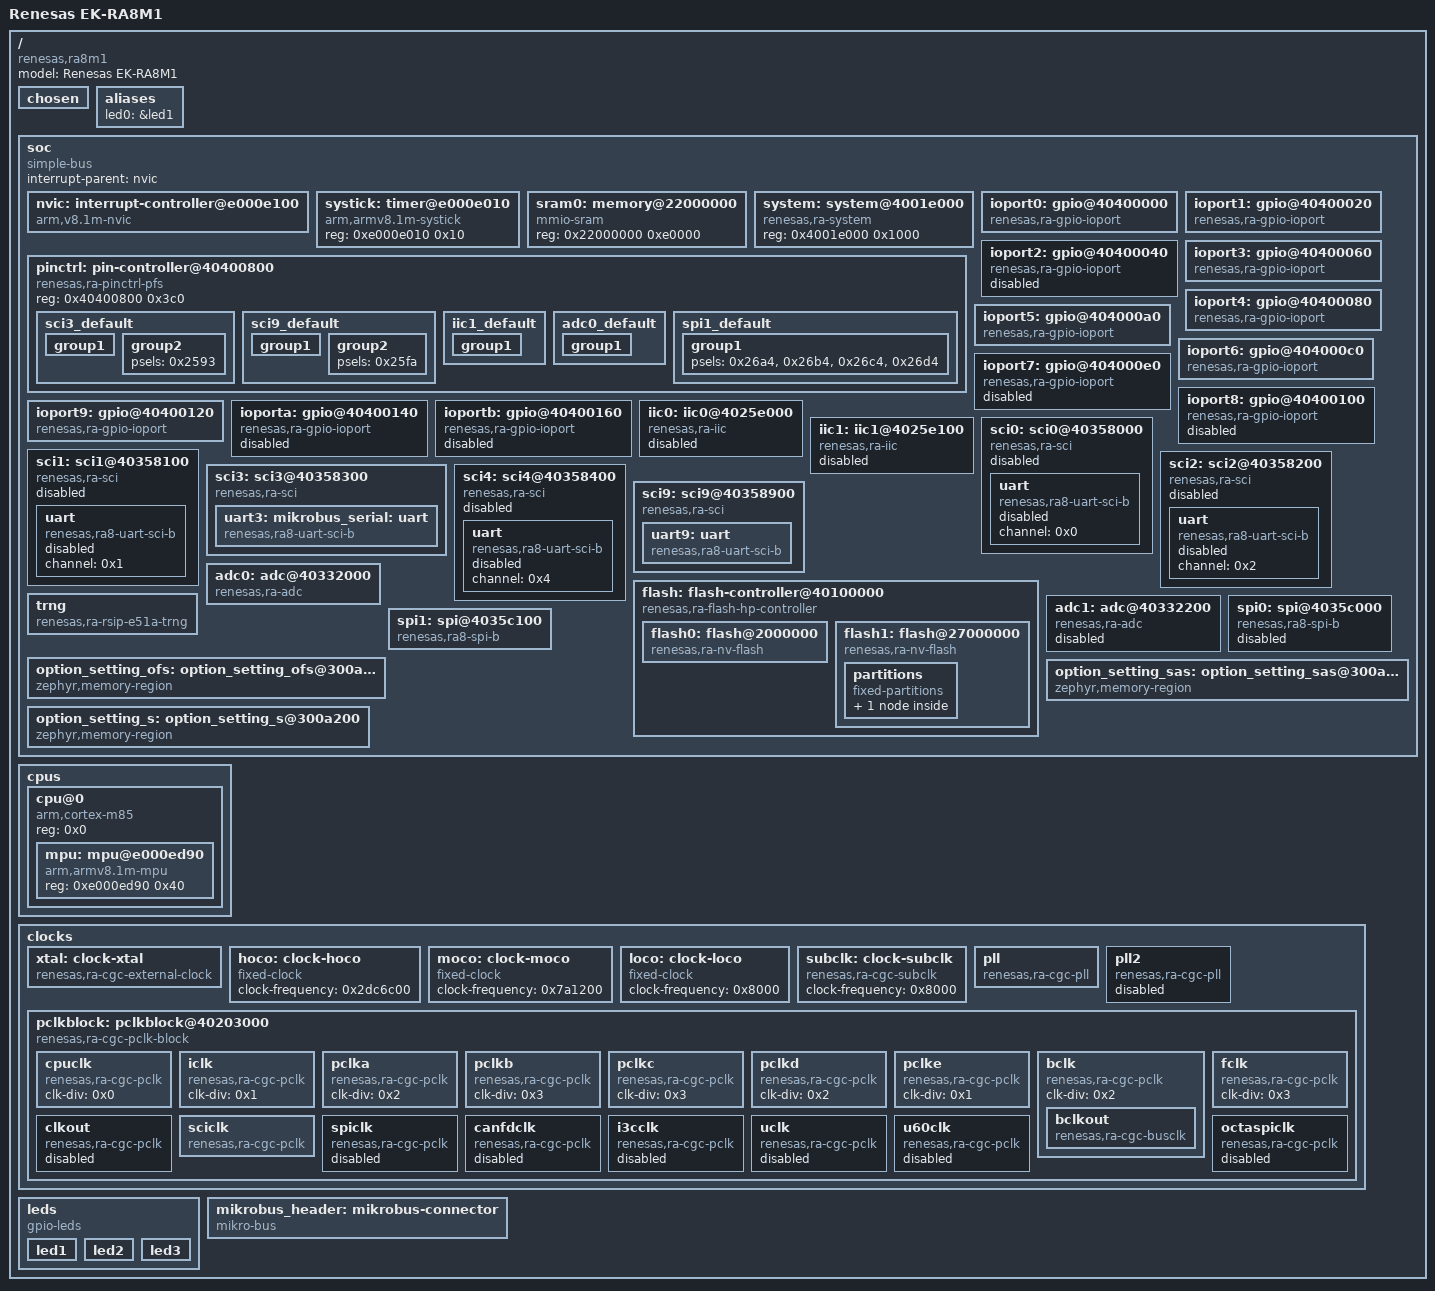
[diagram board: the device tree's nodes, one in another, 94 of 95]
/dts-v1/;

/ {
	#address-cells = < 0x1 >;
	#size-cells = < 0x1 >;
	model = "Renesas EK-RA8M1";
	compatible = "renesas,ra8m1", "renesas,ra8";
	chosen {
		zephyr,sram = &sram0;
		zephyr,flash-controller = &flash1;
		zephyr,flash = &flash0;
		zephyr,console = &uart9;
		zephyr,shell-uart = &uart9;
		zephyr,entropy = &trng;
	};
	aliases {
		led0 = &led1;
	};
	soc {
		#address-cells = < 0x1 >;
		#size-cells = < 0x1 >;
		compatible = "simple-bus";
		interrupt-parent = < &nvic >;
		ranges;
		nvic: interrupt-controller@e000e100 {
			#address-cells = < 0x1 >;
			compatible = "arm,v8.1m-nvic";
			reg = < 0xe000e100 0xc00 >;
			interrupt-controller;
			#interrupt-cells = < 0x2 >;
			arm,num-irq-priority-bits = < 0x4 >;
			phandle = < 0x1 >;
		};
		systick: timer@e000e010 {
			compatible = "arm,armv8.1m-systick";
			reg = < 0xe000e010 0x10 >;
		};
		sram0: memory@22000000 {
			compatible = "mmio-sram";
			reg = < 0x22000000 0xe0000 >;
		};
		system: system@4001e000 {
			compatible = "renesas,ra-system";
			reg = < 0x4001e000 0x1000 >;
			status = "okay";
		};
		pinctrl: pin-controller@40400800 {
			compatible = "renesas,ra-pinctrl-pfs";
			reg = < 0x40400800 0x3c0 >;
			status = "okay";
			sci3_default: sci3_default {
				phandle = < 0x4 >;
				group1 {
					psels = < 0x25a3 >;
					drive-strength = "medium";
				};
				group2 {
					psels = < 0x2593 >;
				};
			};
			sci9_default: sci9_default {
				phandle = < 0x5 >;
				group1 {
					psels = < 0x25ea >;
					drive-strength = "medium";
				};
				group2 {
					psels = < 0x25fa >;
				};
			};
			iic1_default: iic1_default {
				phandle = < 0x2 >;
				group1 {
					psels = < 0x27c5 >, < 0x27b5 >;
					drive-strength = "medium";
				};
			};
			adc0_default: adc0_default {
				phandle = < 0x6 >;
				group1 {
					psels = < 0x2040 >;
					renesas,analog-enable;
				};
			};
			spi1_default: spi1_default {
				phandle = < 0x8 >;
				group1 {
					psels = < 0x26a4 >, < 0x26b4 >, < 0x26c4 >, < 0x26d4 >;
				};
			};
		};
		ioport0: gpio@40400000 {
			compatible = "renesas,ra-gpio-ioport";
			reg = < 0x40400000 0x20 >;
			port = < 0x0 >;
			gpio-controller;
			#gpio-cells = < 0x2 >;
			ngpios = < 0x10 >;
			status = "okay";
			phandle = < 0xc >;
		};
		ioport1: gpio@40400020 {
			compatible = "renesas,ra-gpio-ioport";
			reg = < 0x40400020 0x20 >;
			port = < 0x1 >;
			gpio-controller;
			#gpio-cells = < 0x2 >;
			ngpios = < 0x10 >;
			status = "okay";
			phandle = < 0xb >;
		};
		ioport2: gpio@40400040 {
			compatible = "renesas,ra-gpio-ioport";
			reg = < 0x40400040 0x20 >;
			port = < 0x2 >;
			gpio-controller;
			#gpio-cells = < 0x2 >;
			ngpios = < 0x10 >;
			status = "disabled";
		};
		ioport3: gpio@40400060 {
			compatible = "renesas,ra-gpio-ioport";
			reg = < 0x40400060 0x20 >;
			port = < 0x3 >;
			gpio-controller;
			#gpio-cells = < 0x2 >;
			ngpios = < 0x10 >;
			status = "okay";
			phandle = < 0xf >;
		};
		ioport4: gpio@40400080 {
			compatible = "renesas,ra-gpio-ioport";
			reg = < 0x40400080 0x20 >;
			port = < 0x4 >;
			gpio-controller;
			#gpio-cells = < 0x2 >;
			ngpios = < 0x10 >;
			vbatts_pins = < 0x2 0x3 0x4 >;
			status = "okay";
			phandle = < 0xa >;
		};
		ioport5: gpio@404000a0 {
			compatible = "renesas,ra-gpio-ioport";
			reg = < 0x404000a0 0x20 >;
			port = < 0x5 >;
			gpio-controller;
			#gpio-cells = < 0x2 >;
			ngpios = < 0x10 >;
			status = "okay";
			phandle = < 0xd >;
		};
		ioport6: gpio@404000c0 {
			compatible = "renesas,ra-gpio-ioport";
			reg = < 0x404000c0 0x20 >;
			port = < 0x6 >;
			gpio-controller;
			#gpio-cells = < 0x2 >;
			ngpios = < 0x10 >;
			status = "okay";
			phandle = < 0x9 >;
		};
		ioport7: gpio@404000e0 {
			compatible = "renesas,ra-gpio-ioport";
			reg = < 0x404000e0 0x20 >;
			port = < 0x7 >;
			gpio-controller;
			#gpio-cells = < 0x2 >;
			ngpios = < 0x10 >;
			status = "disabled";
		};
		ioport8: gpio@40400100 {
			compatible = "renesas,ra-gpio-ioport";
			reg = < 0x40400100 0x20 >;
			port = < 0x8 >;
			gpio-controller;
			#gpio-cells = < 0x2 >;
			ngpios = < 0x10 >;
			status = "disabled";
		};
		ioport9: gpio@40400120 {
			compatible = "renesas,ra-gpio-ioport";
			reg = < 0x40400120 0x20 >;
			port = < 0x9 >;
			gpio-controller;
			#gpio-cells = < 0x2 >;
			ngpios = < 0x10 >;
			status = "okay";
			phandle = < 0xe >;
		};
		ioporta: gpio@40400140 {
			compatible = "renesas,ra-gpio-ioport";
			reg = < 0x40400140 0x20 >;
			port = < 0xa >;
			gpio-controller;
			#gpio-cells = < 0x2 >;
			ngpios = < 0x10 >;
			status = "disabled";
		};
		ioportb: gpio@40400160 {
			compatible = "renesas,ra-gpio-ioport";
			reg = < 0x40400160 0x20 >;
			port = < 0xb >;
			gpio-controller;
			#gpio-cells = < 0x2 >;
			ngpios = < 0x10 >;
			status = "disabled";
		};
		iic0: iic0@4025e000 {
			compatible = "renesas,ra-iic";
			channel = < 0x0 >;
			interrupts = < 0x57 0x1 >, < 0x58 0x1 >, < 0x59 0x1 >, < 0x5a 0x1 >;
			interrupt-names = "rxi", "txi", "tei", "eri";
			reg = < 0x4025e000 0x100 >;
			status = "disabled";
		};
		iic1: iic1@4025e100 {
			compatible = "renesas,ra-iic";
			channel = < 0x1 >;
			interrupts = < 0x5b 0x1 >, < 0x5c 0x1 >, < 0x5d 0x1 >, < 0x5e 0x1 >;
			interrupt-names = "rxi", "txi", "tei", "eri";
			reg = < 0x4025e100 0x100 >;
			status = "disabled";
			#address-cells = < 0x1 >;
			#size-cells = < 0x0 >;
			clock-frequency = < 0xf4240 >;
			pinctrl-0 = < &iic1_default >;
			pinctrl-names = "default";
		};
		sci0: sci0@40358000 {
			compatible = "renesas,ra-sci";
			interrupts = < 0x4 0x1 >, < 0x5 0x1 >, < 0x6 0x1 >, < 0x7 0x1 >;
			interrupt-names = "rxi", "txi", "tei", "eri";
			reg = < 0x40358000 0x100 >;
			clocks = < &sciclk 0x1 0x1f >;
			status = "disabled";
			uart {
				compatible = "renesas,ra8-uart-sci-b";
				channel = < 0x0 >;
				status = "disabled";
			};
		};
		sci1: sci1@40358100 {
			compatible = "renesas,ra-sci";
			interrupts = < 0x8 0x1 >, < 0x9 0x1 >, < 0xa 0x1 >, < 0xb 0x1 >;
			interrupt-names = "rxi", "txi", "tei", "eri";
			reg = < 0x40358100 0x100 >;
			clocks = < &sciclk 0x1 0x1e >;
			status = "disabled";
			uart {
				compatible = "renesas,ra8-uart-sci-b";
				channel = < 0x1 >;
				status = "disabled";
			};
		};
		sci2: sci2@40358200 {
			compatible = "renesas,ra-sci";
			interrupts = < 0xc 0x1 >, < 0xd 0x1 >, < 0xe 0x1 >, < 0xf 0x1 >;
			interrupt-names = "rxi", "txi", "tei", "eri";
			reg = < 0x40358200 0x100 >;
			clocks = < &sciclk 0x1 0x1d >;
			status = "disabled";
			uart {
				compatible = "renesas,ra8-uart-sci-b";
				channel = < 0x2 >;
				status = "disabled";
			};
		};
		sci3: sci3@40358300 {
			compatible = "renesas,ra-sci";
			interrupts = < 0x10 0x1 >, < 0x11 0x1 >, < 0x12 0x1 >, < 0x13 0x1 >;
			interrupt-names = "rxi", "txi", "tei", "eri";
			reg = < 0x40358300 0x100 >;
			clocks = < &sciclk 0x1 0x1c >;
			status = "okay";
			pinctrl-0 = < &sci3_default >;
			pinctrl-names = "default";
			uart3: mikrobus_serial: uart {
				compatible = "renesas,ra8-uart-sci-b";
				channel = < 0x3 >;
				status = "okay";
				current-speed = < 0x1c200 >;
			};
		};
		sci4: sci4@40358400 {
			compatible = "renesas,ra-sci";
			interrupts = < 0x14 0x1 >, < 0x15 0x1 >, < 0x16 0x1 >, < 0x17 0x1 >;
			interrupt-names = "rxi", "txi", "tei", "eri";
			reg = < 0x40358400 0x100 >;
			clocks = < &sciclk 0x1 0x1b >;
			status = "disabled";
			uart {
				compatible = "renesas,ra8-uart-sci-b";
				channel = < 0x4 >;
				status = "disabled";
			};
		};
		sci9: sci9@40358900 {
			compatible = "renesas,ra-sci";
			interrupts = < 0x18 0x1 >, < 0x19 0x1 >, < 0x1a 0x1 >, < 0x1b 0x1 >;
			interrupt-names = "rxi", "txi", "tei", "eri";
			reg = < 0x40358900 0x100 >;
			clocks = < &sciclk 0x1 0x16 >;
			status = "okay";
			pinctrl-0 = < &sci9_default >;
			pinctrl-names = "default";
			uart9: uart {
				compatible = "renesas,ra8-uart-sci-b";
				channel = < 0x9 >;
				status = "okay";
				current-speed = < 0x1c200 >;
			};
		};
		flash: flash-controller@40100000 {
			compatible = "renesas,ra-flash-hp-controller";
			reg = < 0x40100000 0x20000 >;
			#address-cells = < 0x1 >;
			#size-cells = < 0x1 >;
			interrupts = < 0x31 0x1 >, < 0x32 0x1 >;
			interrupt-names = "frdyi", "fiferr";
			flash0: flash@2000000 {
				compatible = "renesas,ra-nv-flash";
				reg = < 0x2000000 0x1f8000 >;
				write-block-size = < 0x80 >;
				erase-block-size = < 0x2000 >;
				renesas,programming-enable;
			};
			flash1: flash@27000000 {
				compatible = "renesas,ra-nv-flash";
				reg = < 0x27000000 0x3000 >;
				write-block-size = < 0x4 >;
				erase-block-size = < 0x40 >;
				renesas,programming-enable;
				partitions {
					compatible = "fixed-partitions";
					#address-cells = < 0x1 >;
					#size-cells = < 0x1 >;
					storage_partition: partition@0 {
						label = "storage";
						reg = < 0x0 0x3000 >;
					};
				};
			};
		};
		adc0: adc@40332000 {
			compatible = "renesas,ra-adc";
			interrupts = < 0x26 0x1 >;
			interrupt-names = "scanend";
			reg = < 0x40332000 0x100 >;
			#io-channel-cells = < 0x1 >;
			vref-mv = < 0xce4 >;
			channel-count = < 0xc >;
			status = "okay";
			pinctrl-0 = < &adc0_default >;
			pinctrl-names = "default";
		};
		adc1: adc@40332200 {
			compatible = "renesas,ra-adc";
			interrupts = < 0x27 0x1 >;
			interrupt-names = "scanend";
			reg = < 0x40332200 0x100 >;
			#io-channel-cells = < 0x1 >;
			vref-mv = < 0xce4 >;
			channel-count = < 0xd >;
			status = "disabled";
		};
		trng: trng {
			compatible = "renesas,ra-rsip-e51a-trng";
			status = "okay";
		};
		spi0: spi@4035c000 {
			compatible = "renesas,ra8-spi-b";
			#address-cells = < 0x1 >;
			#size-cells = < 0x0 >;
			channel = < 0x0 >;
			clocks = < &pclka 0x1 0x13 >;
			clock-names = "spiclk";
			interrupts = < 0x1c 0x1 >, < 0x1d 0x1 >, < 0x1e 0x1 >, < 0x1f 0x1 >;
			interrupt-names = "rxi", "txi", "tei", "eri";
			reg = < 0x4035c000 0x100 >;
			status = "disabled";
		};
		spi1: spi@4035c100 {
			compatible = "renesas,ra8-spi-b";
			#address-cells = < 0x1 >;
			#size-cells = < 0x0 >;
			channel = < 0x1 >;
			clocks = < &pclka 0x1 0x12 >;
			clock-names = "spiclk";
			interrupts = < 0x20 0x1 >, < 0x21 0x1 >, < 0x22 0x1 >, < 0x23 0x1 >;
			interrupt-names = "rxi", "txi", "tei", "eri";
			reg = < 0x4035c100 0x100 >;
			status = "okay";
			pinctrl-0 = < &spi1_default >;
			pinctrl-names = "default";
		};
		option_setting_ofs: option_setting_ofs@300a100 {
			compatible = "zephyr,memory-region";
			reg = < 0x300a100 0x18 >;
			zephyr,memory-region = "OPTION_SETTING_OFS";
			status = "okay";
		};
		option_setting_sas: option_setting_sas@300a134 {
			compatible = "zephyr,memory-region";
			reg = < 0x300a134 0xcc >;
			zephyr,memory-region = "OPTION_SETTING_SAS";
			status = "okay";
		};
		option_setting_s: option_setting_s@300a200 {
			compatible = "zephyr,memory-region";
			reg = < 0x300a200 0x100 >;
			zephyr,memory-region = "OPTION_SETTING_S";
			status = "okay";
		};
	};
	cpus {
		#address-cells = < 0x1 >;
		#size-cells = < 0x0 >;
		cpu@0 {
			device_type = "cpu";
			compatible = "arm,cortex-m85";
			reg = < 0x0 >;
			#address-cells = < 0x1 >;
			#size-cells = < 0x1 >;
			mpu: mpu@e000ed90 {
				compatible = "arm,armv8.1m-mpu";
				reg = < 0xe000ed90 0x40 >;
			};
		};
	};
	clocks: clocks {
		#address-cells = < 0x1 >;
		#size-cells = < 0x1 >;
		xtal: clock-xtal {
			compatible = "renesas,ra-cgc-external-clock";
			clock-frequency = < 0x1312d00 >;
			#clock-cells = < 0x0 >;
			status = "okay";
			mosel = < 0x0 >;
		};
		hoco: clock-hoco {
			compatible = "fixed-clock";
			clock-frequency = < 0x2dc6c00 >;
			#clock-cells = < 0x0 >;
		};
		moco: clock-moco {
			compatible = "fixed-clock";
			clock-frequency = < 0x7a1200 >;
			#clock-cells = < 0x0 >;
		};
		loco: clock-loco {
			compatible = "fixed-clock";
			clock-frequency = < 0x8000 >;
			#clock-cells = < 0x0 >;
		};
		subclk: clock-subclk {
			compatible = "renesas,ra-cgc-subclk";
			clock-frequency = < 0x8000 >;
			#clock-cells = < 0x0 >;
			status = "okay";
		};
		pll: pll {
			compatible = "renesas,ra-cgc-pll";
			#clock-cells = < 0x0 >;
			source = < 0x3 >;
			div = < 0x1 >;
			mul = < 0x60 0x0 >;
			divp = < 0x1 >;
			freqp = < 0x1c9c3800 >;
			divq = < 0x1 >;
			freqq = < 0x1c9c3800 >;
			divr = < 0x1 >;
			freqr = < 0x1c9c3800 >;
			status = "okay";
		};
		pll2: pll2 {
			compatible = "renesas,ra-cgc-pll";
			#clock-cells = < 0x0 >;
			source = < 0xff >;
			div = < 0x1 >;
			mul = < 0x60 0x0 >;
			divp = < 0x1 >;
			freqp = < 0x0 >;
			divq = < 0x1 >;
			freqq = < 0x0 >;
			divr = < 0x1 >;
			freqr = < 0x0 >;
			status = "disabled";
		};
		pclkblock: pclkblock@40203000 {
			compatible = "renesas,ra-cgc-pclk-block";
			reg = < 0x40203000 0x4 >, < 0x40203004 0x4 >, < 0x40203008 0x4 >, < 0x4020300c 0x4 >, < 0x40203010 0x4 >;
			reg-names = "MSTPA", "MSTPB", "MSTPC", "MSTPD", "MSTPE";
			#clock-cells = < 0x0 >;
			sysclock-src = < 0x5 >;
			status = "okay";
			cpuclk: cpuclk {
				compatible = "renesas,ra-cgc-pclk";
				clk-div = < 0x0 >;
				#clock-cells = < 0x2 >;
				status = "okay";
			};
			iclk: iclk {
				compatible = "renesas,ra-cgc-pclk";
				clk-div = < 0x1 >;
				#clock-cells = < 0x2 >;
				status = "okay";
			};
			pclka: pclka {
				compatible = "renesas,ra-cgc-pclk";
				clk-div = < 0x2 >;
				#clock-cells = < 0x2 >;
				status = "okay";
				phandle = < 0x7 >;
			};
			pclkb: pclkb {
				compatible = "renesas,ra-cgc-pclk";
				clk-div = < 0x3 >;
				#clock-cells = < 0x2 >;
				status = "okay";
			};
			pclkc: pclkc {
				compatible = "renesas,ra-cgc-pclk";
				clk-div = < 0x3 >;
				#clock-cells = < 0x2 >;
				status = "okay";
			};
			pclkd: pclkd {
				compatible = "renesas,ra-cgc-pclk";
				clk-div = < 0x2 >;
				#clock-cells = < 0x2 >;
				status = "okay";
			};
			pclke: pclke {
				compatible = "renesas,ra-cgc-pclk";
				clk-div = < 0x1 >;
				#clock-cells = < 0x2 >;
				status = "okay";
			};
			bclk: bclk {
				compatible = "renesas,ra-cgc-pclk";
				clk-div = < 0x2 >;
				#clock-cells = < 0x2 >;
				status = "okay";
				bclkout: bclkout {
					compatible = "renesas,ra-cgc-busclk";
					clk-out-div = < 0x2 >;
					sdclk = < 0x1 >;
					#clock-cells = < 0x0 >;
				};
			};
			fclk: fclk {
				compatible = "renesas,ra-cgc-pclk";
				clk-div = < 0x3 >;
				#clock-cells = < 0x2 >;
				status = "okay";
			};
			clkout: clkout {
				compatible = "renesas,ra-cgc-pclk";
				#clock-cells = < 0x2 >;
				status = "disabled";
			};
			sciclk: sciclk {
				compatible = "renesas,ra-cgc-pclk";
				#clock-cells = < 0x2 >;
				status = "okay";
				clk-src = < 0x5 >;
				clk-div = < 0x2 >;
				phandle = < 0x3 >;
			};
			spiclk: spiclk {
				compatible = "renesas,ra-cgc-pclk";
				#clock-cells = < 0x2 >;
				status = "disabled";
			};
			canfdclk: canfdclk {
				compatible = "renesas,ra-cgc-pclk";
				#clock-cells = < 0x2 >;
				status = "disabled";
			};
			i3cclk: i3cclk {
				compatible = "renesas,ra-cgc-pclk";
				#clock-cells = < 0x2 >;
				status = "disabled";
			};
			uclk: uclk {
				compatible = "renesas,ra-cgc-pclk";
				#clock-cells = < 0x2 >;
				status = "disabled";
			};
			u60clk: u60clk {
				compatible = "renesas,ra-cgc-pclk";
				#clock-cells = < 0x2 >;
				status = "disabled";
			};
			octaspiclk: octaspiclk {
				compatible = "renesas,ra-cgc-pclk";
				#clock-cells = < 0x2 >;
				status = "disabled";
			};
		};
	};
	leds {
		compatible = "gpio-leds";
		led1: led1 {
			gpios = < &ioport6 0x0 0x0 >;
			label = "LED1";
		};
		led2: led2 {
			gpios = < &ioport4 0xe 0x0 >;
			label = "LED2";
		};
		led3: led3 {
			gpios = < &ioport1 0x7 0x0 >;
			label = "LED3";
		};
	};
	mikrobus_header: mikrobus-connector {
		compatible = "mikro-bus";
		#gpio-cells = < 0x2 >;
		gpio-map-mask = < 0xffffffff 0xffffffc0 >;
		gpio-map-pass-thru = < 0x0 0x3f >;
		gpio-map = < 0x0 0x0 &ioport0 0x4 0x0 >, < 0x1 0x0 &ioport5 0x2 0x0 >, < 0x2 0x0 &ioport4 0xd 0x0 >, < 0x3 0x0 &ioport4 0xc 0x0 >, < 0x4 0x0 &ioport4 0xa 0x0 >, < 0x5 0x0 &ioport4 0xb 0x0 >, < 0x6 0x0 &ioport9 0x7 0x0 >, < 0x7 0x0 &ioport0 0xa 0x0 >, < 0x8 0x0 &ioport3 0x9 0x0 >, < 0x9 0x0 &ioport3 0xa 0x0 >, < 0xa 0x0 &ioport4 0x0 0x0 >, < 0xb 0x0 &ioport4 0x1 0x0 >;
	};
};
